# AE1C1F4051920PH0_CM55_HE_View register map
Vendor: Alif Semiconductor; Series: E1; File version: 1.0
CPU: CM55 r1p0, selectable endian, MPU, FPU, double-precision FPU, DSP, VTOR, 8 interrupt priority bits, 1 SAU regions
Registers are 32-bit, read-write, reset 0x0 unless marked. A register's access mark holds for its fields unless they carry their own. Offsets are from the block's base; [hi:lo] are bit positions; {n}, {i} and the like mark numbered series.

## ANA
Base 0x1A60A000
0x00 MISC_CTRL — VBAT Misc Control Register
  [0] SEL_32K — Select 32KHz clock source
    0=Select Ring-Oscillator (LFRC); 1=Select Crystal-Oscillator (LFXO)
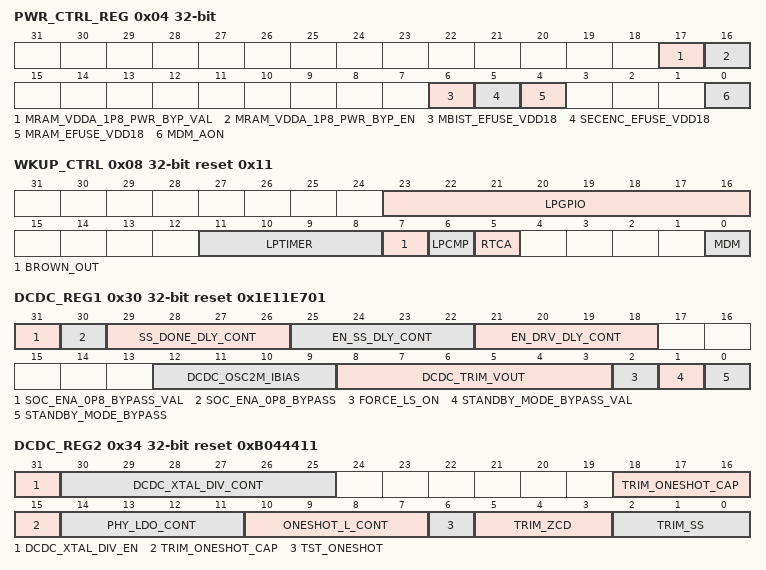
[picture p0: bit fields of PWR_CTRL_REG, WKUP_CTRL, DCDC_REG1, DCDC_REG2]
0x04 PWR_CTRL_REG — VBAT Power Control Register
  [17] MRAM_VDDA_1P8_PWR_BYP_VAL — Power setting for MRAM 1.8 V supply. The setting is used only if MRAM_VDDA_1P8_PWR_BYP_EN bit is enabled.
    0=Power disabled; 1=Power enabled
  [16] MRAM_VDDA_1P8_PWR_BYP_EN — Power mode for MRAM 1.8 V supply
    0=Power enabled whenever PD-6 is enabled; 1=Power specified by MRAM_VDDA_1P8_PWR_BYP_VAL bit
  [6] MBIST_EFUSE_VDD18 — Enable 1.8 V supply for MBIST efuse
    0=Disable; 1=Enable
  [5] SECENC_EFUSE_VDD18 — Enable 1.8 V supply for SE efuse
    0=Disable; 1=Enable
  [4] MRAM_EFUSE_VDD18 — Enable 1.8 V supply for MRAM efuse
    0=Disable; 1=Enable
  [0] MDM_AON — Software controlled BLE Modem AON power. Only if BLE modem is used, then hardware logic will switch on PD-1 and PD-7 concurrently to avoid breaking BLE core logic. SE must set this bit to 0x1 after powering up PD-7 to keep PD1 domain ON forever regardless the power state of the BLE core (PD-7). Once this bit is set, it should never be cleared. Note: PD-7 and PD-1 domains are OFF by default.
    0=Disable; 1=Enable
0x08 WKUP_CTRL reset 0x11 — VBAT Wake-up Source Control Register
  [23:16] LPGPIO — Each bit controls enable/disable of a wake-up source from LPGPIO
    0=Disable wake-up source; 1=Enable wake-up source
  [11:8] LPTIMER — Each bit controls enable/disable of a wake-up source from LPTIMER
    0=Disable wake-up source; 1=Enable wake-up source
  [7] BROWN_OUT — Controls enable/disable of wake-up source from Brown-Out Detect (Falling Edge). This register bit is also used to clear the wake-up source by SE CPU.
    0=Disable and Clear wake-up source; 1=Enable wake-up source
  [6] LPCMP — Controls enable/disable of wake-up source from LPCMP
    0=Disable wake-up source; 1=Enable wake-up source
  [5] RTCA — Controls enable/disable of wake-up source from LPRTC0
    0=Disable wake-up source; 1=Enable wake-up source
  [0] MDM — Controls enable/disable of wake-up source from BLE Modem AON
    0=Disable wake-up source; 1=Enable wake-up source
0x24 CM55_HE_SE_VTOR — 25-bit M55-HE Secure VTOR Register
  [31:7] VCTR — Bits [31:7] of vector table base address. Bits [6:0] are discarded.
0x30 DCDC_REG1 reset 0x1E11E701 — DC/DC Control Register 1
  [31] SOC_ENA_0P8_BYPASS_VAL — When low, AON and RET LDOs Vout can be programmed independent of SOC_ENA_0p8 state.
  [30] SOC_ENA_0P8_BYPASS — When low, AON and RET LDOs VCTRL state is set by bit [SOC_ENA_0P8_BYPASS_VAL]. When high, AON and RET LDOs VCTRL state is set by SOC_ENA_0p8.
  [29:26] SS_DONE_DLY_CONT — Delay control for SS disable. Min: 0000 = 0 clock cycles delay Max: 1111 = 15 clock cycles delay Clock is DC-DC clock divided by 64 (~31kHz for nominal settings)
  [25:22] EN_SS_DLY_CONT — Trim EN_SS signal delay: Min is 0000: 0 clock cycles delay Max is 1111: 15 clock cycles delay Clock is DC-DC clock divided by 8 (~250 kHz for nominal settings)
  [21:18] EN_DRV_DLY_CONT — Trim EN_DRV signal delay: Min is 0000 = 0 clock cycles delay Max is 1111 = 15 clock cycles delay Clock is DC-DC clock divided by 8 (~250 kHz for nominal settings)
  [12:9] DCDC_OSC2M_IBIAS — Trim DC-DC 2-MHz internal oscillator: Min is 0000: 1.5 MHz Max is 1111: 3.75 MHz LSB step = ~0.15 MHz
  [8:3] DCDC_TRIM_VOUT — DC-DC output voltage trim. Each LSB is 1% = 8mV
    32=mid code = 825 mV DC-DC voltage (on low side of ripple; high side will be some mV above this based on inductor and Ton)
  [2] FORCE_LS_ON — Force low-side Power FET to be on (NMOS Power FET), PWM signal will be kept low.
  [1] STANDBY_MODE_BYPASS_VAL — Puts the PMU in Standby mode by overriding the bit sent from digital/SW.
  [0] STANDBY_MODE_BYPASS — Standby mode control:
    0=Standby mode is controlled by bit [STANDBY_MODE_BYPASS_VAL]; 1=Standby mode is determined by the bit sent from digital/SW
0x34 DCDC_REG2 reset 0xB044411 — DC/DC Control Register 2
  [31] DCDC_XTAL_DIV_EN — Enable DC-DC high-frequency XTAL frequency divider.
    0=Disable; 1=Enable
  [30:25] DCDC_XTAL_DIV_CONT — High-frequency XTAL frequency divider division value: Fout = Fxtal / (2 x DCDC_XTAL_DIV_CONT)
  [18:15] TRIM_ONESHOT_CAP — Trim one-shot capacitor.
  [14:11] PHY_LDO_CONT — MIPI PHY LDO (LDO-6) output voltage control: Step: 20 mV
    0=Val_0b0000 (1.6 V); 15=Val_0b1111 (1.9 V)
  [10:7] ONESHOT_L_CONT — One-shot control.
  [6] TST_ONESHOT — Enable test mode for one shot.
  [5:3] TRIM_ZCD — Trim for PFM ZCD comparator offset voltage.
  [2:0] TRIM_SS — Trim for soft start timing: Step: 5 us
    0=Val_0b000 (10 us); 7=Val_0b111 (45 us)
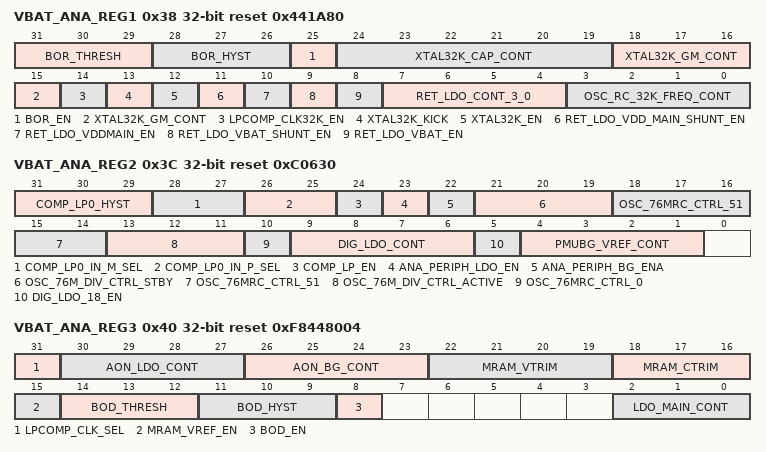
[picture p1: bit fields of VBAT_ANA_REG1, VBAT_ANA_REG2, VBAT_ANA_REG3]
0x38 VBAT_ANA_REG1 reset 0x441A80 — VBAT Analog Control Register 1
  [31:29] BOR_THRESH — Control for BOR threshold level: Step: 22.857 mV
    0=Val_0b000 (1.585 V); 7=Val_0b111 (1.745 V)
  [28:26] BOR_HYST — Control for BOR hysteresis: Step: 22.857 mV
    0=Val_0b000 (0 mV); 7=Val_0b111 (160 mV)
  [25] BOR_EN — Enables BOR circuit.
    0=Disable; 1=Enable
  [24:19] XTAL32K_CAP_CONT — Shunt capacitor control for 32-kHz XTAL oscillator: Step: 0.25 pF
    0=Val_0b000000 (2 pF); 63=Val_0b111111 (16 pF)
  [18:15] XTAL32K_GM_CONT — gM control for 32-kHz XTAL oscillator:
    0=Val_0b0000 (no gM (off)); 15=Val_0b1111 (max gM)
  [14] LPCOMP_CLK32K_EN — Enables 32-kHz clock to LPCMP comparator.
  [13] XTAL32K_KICK — Starts 32-kHz XTAL oscillator.
  [12] XTAL32K_EN — Enables 32-kHz XTAL oscillator.
  [11] RET_LDO_VDD_MAIN_SHUNT_EN — Enables 38-Mohm shunt resistor on LDO-2.
  [10] RET_LDO_VDDMAIN_EN — Enables LDO-2 for SE SRAM and M55-HE TCM retention.
  [9] RET_LDO_VBAT_SHUNT_EN — Enables 38-Mohm shunt resistor on LDO-0.
  [8] RET_LDO_VBAT_EN — Enables LDO-0 for AON Utility SRAM retention.
  [7:4] RET_LDO_CONT_3_0 — Controls both LDO-0 and LDO-2 output voltages: Step: 22.2 mV
    0=Val_0b0000 (500 mV); 15=Val_0b1111 (833 mV)
  [3:0] OSC_RC_32K_FREQ_CONT — Controls NTAT current into 32-kHz RC oscillator.
0x3C VBAT_ANA_REG2 reset 0xC0630 — VBAT Analog Control Register 2
  [31:29] COMP_LP0_HYST — Sets LPCMP hysteresis level. Step: 6.43 mV
    0=0 mV; 7=45 mV
  [28:27] COMP_LP0_IN_M_SEL — Selects input to negative terminal of LPCMP:
    0=Internal AON Vref (0.8 V); 1=VREF_IN0 pin; 2=VREF_IN1 pin; 3=VREF_IN2 pin
  [26:25] COMP_LP0_IN_P_SEL — Selects input to positive terminal of LPCMP:
    {v}=LPCMP_IN{v} pin (v=0..3)
  [24] COMP_LP_EN — Enable LPCMP.
  [23] ANA_PERIPH_LDO_EN — Enable Analog Peripherals LDO (LDO-5).
  [22] ANA_PERIPH_BG_ENA — Enable precision bandgap for analog peripherals.
  [21:19] OSC_76M_DIV_CTRL_STBY — 76-MHz oscillator divider control in STANDBY mode.
    0=76.8 MHz; 1=38.4 MHz; 2=19.2 MHz; 3=4.8 MHz; 4=1.2 MHz; 5=600 kHz; 6=300 kHz; 7=75 kHz
  [18:14] OSC_76MRC_CTRL_51 — Control for 76-MHz RC oscillator frequency (bits [5-1] of a 6-bit value). Used with bit OSC_76MRC_CTRL_0 (bit[0] of the 6-bit value). Step: 1.3%
    0=Val_0b00000 (-10% (bit OSC_76MRC_CTRL_0 = 0)); 31=Val_0b11111 (+10% (bit OSC_76MRC_CTRL_0 = 1))
  [13:11] OSC_76M_DIV_CTRL_ACTIVE — 76-MHz oscillator divider control in GO, READY, and IDLE modes.
    0=76.8 MHz; 1=38.4 MHz; 2=19.2 MHz; 3=9.6 MHz; 4=4.8 MHz; 5=2.4 MHz; 6=1.2 MHz; 7=600 kHz
  [10] OSC_76MRC_CTRL_0 — Control for 76-MHz RC oscillator frequency (bit[0] of a 6-bit value). Used with [OSC_76MRC_CTRL_51] field.
  [9:6] DIG_LDO_CONT — LDO-4 output voltage control: Step: 20 mV
    0=Val_0b0000 (1.58 V); 15=Val_0b1111 (1.88 V)
  [5] DIG_LDO_18_EN — Enables 1.8-V digital LDO (LDO-4). Used for MRAM and EFUSE.
  [4:1] PMUBG_VREF_CONT — Calibration for PMU bandgap: Step: 1%
    0=Val_0b0000 (-7%); 15=Val_0b1111 (+8%)
0x40 VBAT_ANA_REG3 reset 0xF8448004 — VBAT Analog Control Register 3
  [31] LPCOMP_CLK_SEL — Selects clock source for LPCMP:
    0=32-kHz XTAL oscillator (LFXO); 1=32-kHz RC oscillator (LFRC)
  [30:27] AON_LDO_CONT — AON LDO (LDO-1) output voltage trim: Step: 10.67 mV
    0=Val_0b0000 (660 mV); 15=Val_0b1111 (820 mV)
  [26:23] AON_BG_CONT — AON bandgap voltage trim Step: 9.67 mV
    0=Val_0b0000 (830 mV); 15=Val_0b1111 (685 mV)
  [22:19] MRAM_VTRIM — MRAM offset trim
  [18:16] MRAM_CTRIM — MRAM curvature trim
  [15] MRAM_VREF_EN — Enables MRAM VREF block
  [14:12] BOD_THRESH — Control for BOD threshold level: Step: 22.857 mV
    0=Val_0b000 (1.585 V); 7=Val_0b111 (1.745 V)
  [11:9] BOD_HYST — Control for BOD hysteresis: Step: 22.857 mV
    0=Val_0b000 (0 mV); 7=Val_0b111 (160 mV)
  [8] BOD_EN — Enables BOD circuit.
    0=Disable; 1=Enable
  [2:0] LDO_MAIN_CONT — PMU 1.8-V LDO (LDO-3) output voltage control: Step = 21.43 mV
    0=Val_0b000 (1.71 V); 7=Val_0b111 (1.86 V)
